VERSION ""

NS_ :

BS_:

BU_: XXX

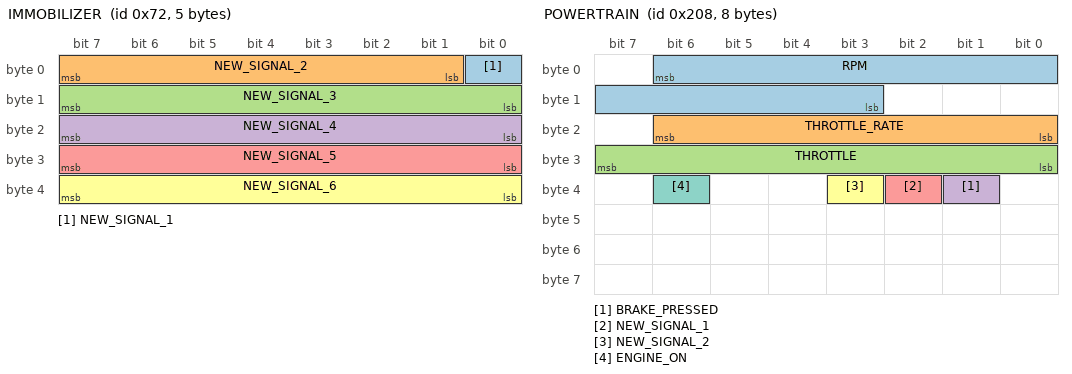
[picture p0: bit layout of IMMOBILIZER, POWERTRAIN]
BO_ 114 IMMOBILIZER: 5 XXX
 SG_ NEW_SIGNAL_1 : 0|1@0+ (1,0) [0|1] "" XXX
 SG_ NEW_SIGNAL_2 : 7|7@0+ (1,0) [0|127] "" XXX
 SG_ NEW_SIGNAL_3 : 15|8@0+ (1,0) [0|255] "" XXX
 SG_ NEW_SIGNAL_4 : 23|8@0+ (1,0) [0|255] "" XXX
 SG_ NEW_SIGNAL_5 : 31|8@0+ (1,0) [0|255] "" XXX
 SG_ NEW_SIGNAL_6 : 39|8@0+ (1,0) [0|255] "" XXX

BO_ 520 POWERTRAIN: 8 XXX
 SG_ RPM : 6|12@0+ (1,0) [0|8191] "" XXX
 SG_ THROTTLE_RATE : 22|7@0+ (1,0) [0|127] "" XXX
 SG_ THROTTLE : 31|8@0+ (0.5,0) [0|255] "" XXX
 SG_ BRAKE_PRESSED : 33|1@0+ (1,0) [0|1] "" XXX
 SG_ NEW_SIGNAL_1 : 34|1@0+ (1,0) [0|1] "" XXX
 SG_ NEW_SIGNAL_2 : 35|1@0+ (1,0) [0|1] "" XXX
 SG_ ENGINE_ON : 38|1@0+ (1,0) [0|1] "" XXX

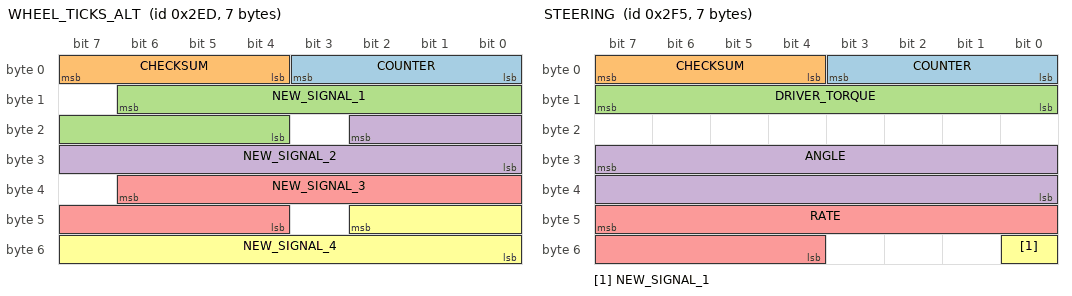
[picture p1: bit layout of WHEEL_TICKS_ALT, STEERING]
BO_ 749 WHEEL_TICKS_ALT: 7 XXX
 SG_ COUNTER : 3|4@0+ (1,0) [0|15] "" XXX
 SG_ CHECKSUM : 7|4@0+ (1,0) [0|15] "" XXX
 SG_ NEW_SIGNAL_1 : 14|11@0+ (1,0) [0|2047] "" XXX
 SG_ NEW_SIGNAL_2 : 18|11@0+ (1,0) [0|2047] "" XXX
 SG_ NEW_SIGNAL_3 : 38|11@0+ (1,0) [0|2047] "" XXX
 SG_ NEW_SIGNAL_4 : 42|11@0+ (1,0) [0|2047] "" XXX

BO_ 757 STEERING: 7 XXX
 SG_ COUNTER : 3|4@0+ (1,0) [0|255] "" XXX
 SG_ CHECKSUM : 7|4@0+ (1,0) [0|15] "" XXX
 SG_ DRIVER_TORQUE : 15|8@0- (1,0) [0|255] "" XXX
 SG_ ANGLE : 31|16@0- (0.1,0) [-3276.8|3276.7] "degrees" XXX
 SG_ RATE : 47|12@0- (1,0) [0|4095] "" XXX
 SG_ NEW_SIGNAL_1 : 48|1@0+ (1,0) [0|1] "" XXX

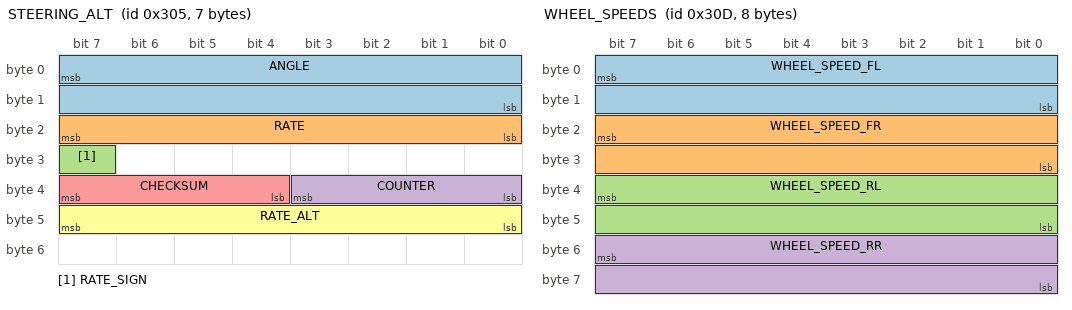
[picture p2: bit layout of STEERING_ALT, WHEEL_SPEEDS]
BO_ 773 STEERING_ALT: 7 XXX
 SG_ ANGLE : 7|16@0- (0.1,0) [-3276.8|3276.7] "degrees" XXX
 SG_ RATE : 23|8@0+ (1,0) [0|255] "" XXX
 SG_ RATE_SIGN : 31|1@0+ (1,0) [0|1] "" XXX
 SG_ COUNTER : 35|4@0+ (1,0) [0|255] "" XXX
 SG_ CHECKSUM : 39|4@0+ (1,0) [0|15] "" XXX
 SG_ RATE_ALT : 47|8@0+ (1,0) [0|255] "" XXX

BO_ 781 WHEEL_SPEEDS: 8 XXX
 SG_ WHEEL_SPEED_FL : 7|16@0+ (0.01,0) [0|65535] "kph" XXX
 SG_ WHEEL_SPEED_FR : 23|16@0+ (0.01,0) [0|65535] "kph" XXX
 SG_ WHEEL_SPEED_RL : 39|16@0+ (0.01,0) [0|65535] "kph" XXX
 SG_ WHEEL_SPEED_RR : 55|16@0+ (0.01,0) [0|65535] "kph" XXX

BO_ 840 BODY_2: 8 XXX
 SG_ GEAR : 7|4@0+ (1,0) [0|15] "" XXX
 SG_ NEW_SIGNAL_2 : 14|7@0+ (1,0) [0|127] "" XXX
 SG_ NEW_SIGNAL_1 : 22|7@0+ (1,0) [0|127] "" XXX
 SG_ NEW_SIGNAL_4 : 30|7@0+ (1,0) [0|127] "" XXX
 SG_ CLUTCH_PRESSED : 35|1@0+ (1,0) [0|1] "" XXX
 SG_ NEW_SIGNAL_9 : 37|1@0+ (1,0) [0|1] "" XXX
 SG_ NEW_SIGNAL_7 : 38|1@0+ (1,0) [0|1] "" XXX
 SG_ NEW_SIGNAL_6 : 39|1@0+ (1,0) [0|1] "" XXX
 SG_ NEW_SIGNAL_3 : 40|1@0+ (1,0) [0|1] "" XXX
 SG_ IGNITION : 41|1@0+ (1,0) [0|1] "" XXX
 SG_ NEW_SIGNAL_8 : 50|1@0+ (1,0) [0|1] "" XXX
 SG_ ENGINE_ON : 53|1@0+ (1,0) [0|1] "" XXX
 SG_ IGNITION_ACCESSORY : 54|1@0+ (1,0) [0|1] "" XXX
 SG_ NEW_SIGNAL_5 : 55|1@0+ (1,0) [0|1] "" XXX
 SG_ NEW_SIGNAL_13 : 56|1@0+ (1,0) [0|1] "" XXX
 SG_ NEW_SIGNAL_14 : 59|1@0+ (1,0) [0|1] "" XXX
 SG_ NEW_SIGNAL_15 : 60|1@0+ (1,0) [0|1] "" XXX

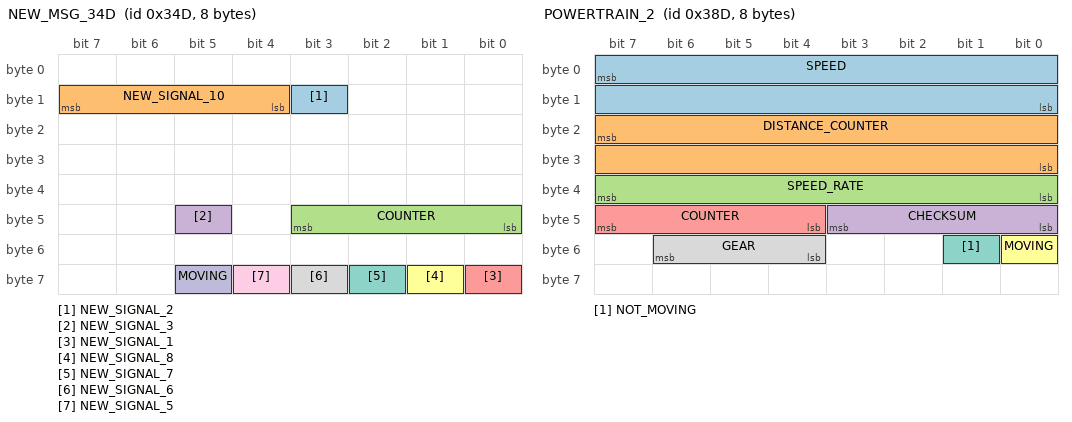
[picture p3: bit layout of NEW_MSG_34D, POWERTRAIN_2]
BO_ 845 NEW_MSG_34D: 8 XXX
 SG_ NEW_SIGNAL_2 : 11|1@0+ (1,0) [0|1] "" XXX
 SG_ NEW_SIGNAL_10 : 15|4@0+ (1,0) [0|15] "" XXX
 SG_ COUNTER : 43|4@0+ (1,0) [0|15] "" XXX
 SG_ NEW_SIGNAL_3 : 45|1@0+ (1,0) [0|1] "" XXX
 SG_ NEW_SIGNAL_1 : 56|1@0+ (1,0) [0|1] "" XXX
 SG_ NEW_SIGNAL_8 : 57|1@0+ (1,0) [0|1] "" XXX
 SG_ NEW_SIGNAL_7 : 58|1@0+ (1,0) [0|1] "" XXX
 SG_ NEW_SIGNAL_6 : 59|1@0+ (1,0) [0|1] "" XXX
 SG_ NEW_SIGNAL_5 : 60|1@0+ (1,0) [0|1] "" XXX
 SG_ MOVING : 61|1@0+ (1,0) [0|1] "" XXX

BO_ 909 POWERTRAIN_2: 8 XXX
 SG_ SPEED : 7|16@0+ (0.01,0) [0|655.35] "kph" XXX
 SG_ DISTANCE_COUNTER : 23|16@0+ (1,0) [0|65535] "" XXX
 SG_ SPEED_RATE : 39|8@0+ (1,-175) [0|255] "" XXX
 SG_ CHECKSUM : 43|4@0+ (1,0) [0|15] "" XXX
 SG_ COUNTER : 47|4@0+ (1,0) [0|15] "" XXX
 SG_ MOVING : 48|1@0+ (1,0) [0|1] "" XXX
 SG_ NOT_MOVING : 49|1@0+ (1,0) [0|1] "" XXX
 SG_ GEAR : 54|3@0+ (1,0) [0|7] "" XXX

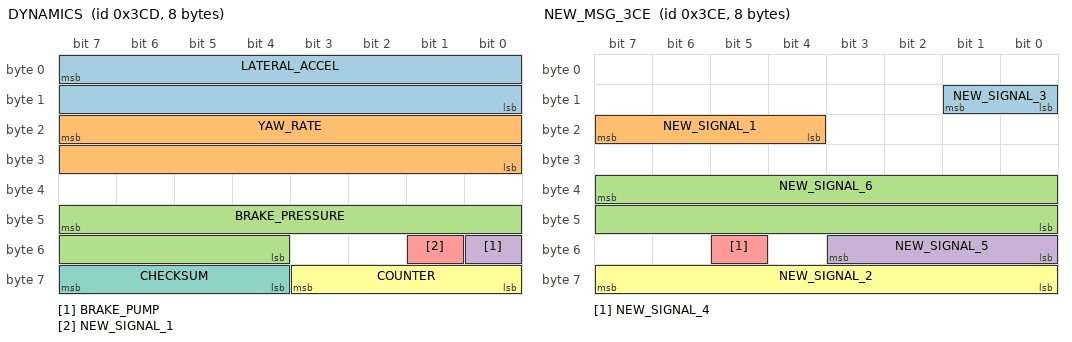
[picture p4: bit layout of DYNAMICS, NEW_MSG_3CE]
BO_ 973 DYNAMICS: 8 XXX
 SG_ LATERAL_ACCEL : 7|16@0- (0.05,0) [-1638.4|1638.35] "m/s^2" XXX
 SG_ YAW_RATE : 23|16@0- (0.1,0) [-3276.8|3276.7] "degrees/s" XXX
 SG_ BRAKE_PRESSURE : 47|12@0+ (1,-550) [0|1500] "" XXX
 SG_ BRAKE_PUMP : 48|1@0+ (1,0) [0|1] "" XXX
 SG_ NEW_SIGNAL_1 : 49|1@0+ (1,0) [0|1] "" XXX
 SG_ COUNTER : 59|4@0+ (1,0) [0|15] "" XXX
 SG_ CHECKSUM : 63|4@0+ (1,0) [0|15] "" XXX

BO_ 974 NEW_MSG_3CE: 8 XXX
 SG_ NEW_SIGNAL_3 : 9|2@0+ (1,0) [0|3] "" XXX
 SG_ NEW_SIGNAL_1 : 23|4@0+ (1,0) [0|15] "" XXX
 SG_ NEW_SIGNAL_6 : 39|16@0+ (1,0) [0|65535] "" XXX
 SG_ NEW_SIGNAL_5 : 51|4@0+ (1,0) [0|15] "" XXX
 SG_ NEW_SIGNAL_4 : 53|1@0+ (1,0) [0|1] "" XXX
 SG_ NEW_SIGNAL_2 : 63|8@0+ (1,0) [0|255] "" XXX

BO_ 1010 LANE_KEEP_ASSIST: 8 XXX
 SG_ NEW_SIGNAL_8 : 0|1@0+ (1,0) [0|1] "" XXX
 SG_ NEW_SIGNAL_1 : 3|3@0+ (1,0) [0|7] "" XXX
 SG_ NEW_SIGNAL_7 : 4|1@0+ (1,0) [0|1] "" XXX
 SG_ NEW_SIGNAL_12 : 5|1@0+ (1,0) [0|1] "" XXX
 SG_ COUNTER : 11|4@0+ (1,0) [0|15] "" XXX
 SG_ CHECKSUM : 15|4@0+ (1,0) [0|15] "" XXX
 SG_ NEW_SIGNAL_6 : 17|2@0+ (1,0) [0|3] "" XXX
 SG_ NEW_SIGNAL_5 : 19|2@0+ (1,0) [0|3] "" XXX
 SG_ LOW_SPEED : 21|2@0+ (1,0) [0|3] "" XXX
 SG_ TORQUE : 31|11@0- (1,0) [0|2047] "" XXX
 SG_ RIGHT_DEPART : 32|1@0+ (1,0) [0|1] "" XXX
 SG_ LEFT_DEPART : 33|1@0+ (1,0) [0|1] "" XXX
 SG_ LKA_DENY : 34|1@0+ (1,0) [0|1] "" XXX
 SG_ STATUS : 35|1@0+ (1,0) [0|1] "" XXX
 SG_ ACTIVE : 36|1@0+ (1,0) [0|1] "" XXX
 SG_ RAMP : 47|7@0+ (1,0) [0|127] "" XXX
 SG_ ANGLE : 55|14@0- (0.1,0) [-90|90] "" XXX
 SG_ NEW_SIGNAL_10 : 57|1@0+ (1,0) [0|1] "" XXX

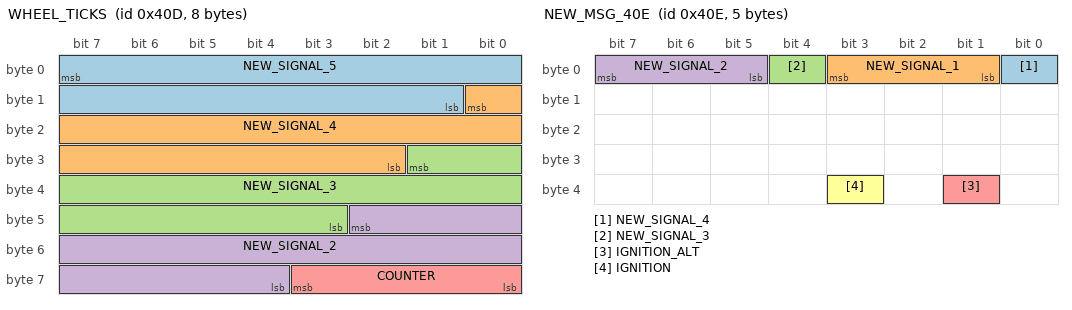
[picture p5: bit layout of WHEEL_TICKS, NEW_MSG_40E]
BO_ 1037 WHEEL_TICKS: 8 XXX
 SG_ NEW_SIGNAL_5 : 7|15@0+ (1,0) [0|32767] "" XXX
 SG_ NEW_SIGNAL_4 : 8|15@0+ (1,0) [0|32767] "" XXX
 SG_ NEW_SIGNAL_3 : 25|15@0+ (1,0) [0|32767] "" XXX
 SG_ NEW_SIGNAL_2 : 42|15@0+ (1,0) [0|32767] "" XXX
 SG_ COUNTER : 59|4@0+ (1,0) [0|15] "" XXX

BO_ 1038 NEW_MSG_40E: 5 XXX
 SG_ NEW_SIGNAL_4 : 0|1@0+ (1,0) [0|1] "" XXX
 SG_ NEW_SIGNAL_1 : 1|3@1+ (1,0) [0|7] "" XXX
 SG_ NEW_SIGNAL_3 : 4|1@0+ (1,0) [0|1] "" XXX
 SG_ NEW_SIGNAL_2 : 5|3@1+ (1,0) [0|7] "" XXX
 SG_ IGNITION_ALT : 33|1@0+ (1,0) [0|1] "" XXX
 SG_ IGNITION : 35|1@0+ (1,0) [0|1] "" XXX

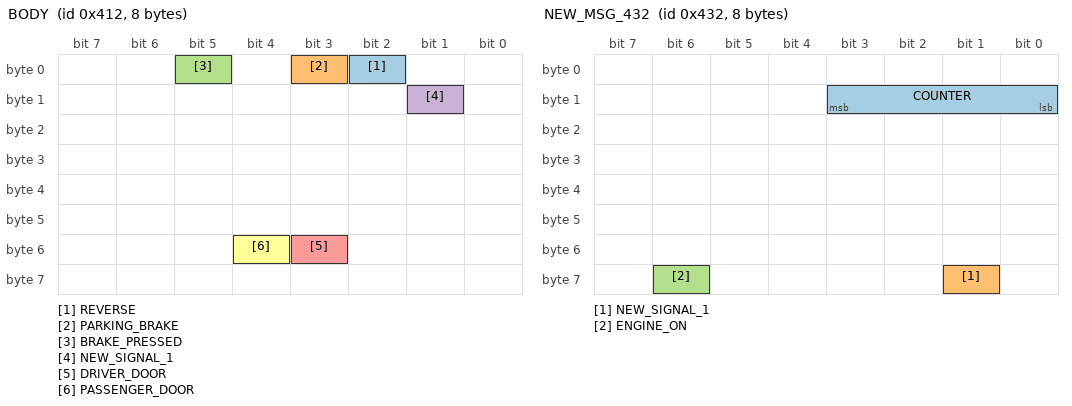
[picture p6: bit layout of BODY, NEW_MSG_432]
BO_ 1042 BODY: 8 XXX
 SG_ REVERSE : 2|1@0+ (1,0) [0|1] "" XXX
 SG_ PARKING_BRAKE : 3|1@0+ (1,0) [0|1] "" XXX
 SG_ BRAKE_PRESSED : 5|1@0+ (1,0) [0|1] "" XXX
 SG_ NEW_SIGNAL_1 : 9|1@0+ (1,0) [0|1] "" XXX
 SG_ DRIVER_DOOR : 51|1@0+ (1,0) [0|1] "" XXX
 SG_ PASSENGER_DOOR : 52|1@0+ (1,0) [0|1] "" XXX

BO_ 1074 NEW_MSG_432: 8 XXX
 SG_ COUNTER : 8|4@1+ (1,0) [0|15] "" XXX
 SG_ NEW_SIGNAL_1 : 57|1@0+ (1,0) [0|1] "" XXX
 SG_ ENGINE_ON : 62|1@0+ (1,0) [0|1] "" XXX

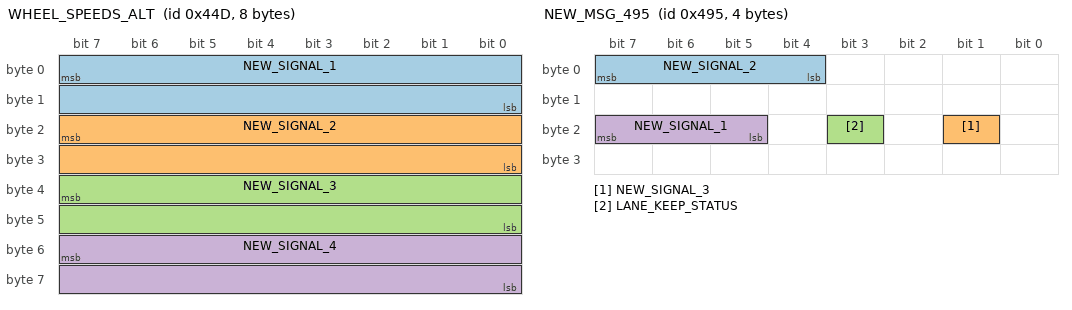
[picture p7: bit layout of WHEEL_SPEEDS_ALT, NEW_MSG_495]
BO_ 1101 WHEEL_SPEEDS_ALT: 8 XXX
 SG_ NEW_SIGNAL_1 : 7|16@0+ (0.01,0) [0|655.35] "kph" XXX
 SG_ NEW_SIGNAL_2 : 23|16@0+ (0.01,0) [0|655.35] "kph" XXX
 SG_ NEW_SIGNAL_3 : 39|16@0+ (0.01,0) [0|655.35] "kph" XXX
 SG_ NEW_SIGNAL_4 : 55|16@0+ (0.005,0) [0|327.675] "kph" XXX

BO_ 1128 NEW_MSG_468: 8 XXX
 SG_ ENGINE_ON2 : 5|1@0+ (1,0) [0|1] "" XXX
 SG_ NEW_SIGNAL_6 : 8|1@0+ (1,0) [0|1] "" XXX
 SG_ NEW_SIGNAL_7 : 10|1@0+ (1,0) [0|1] "" XXX
 SG_ ENGINE_ON : 11|1@0+ (1,0) [0|1] "" XXX
 SG_ NEW_SIGNAL_2 : 13|2@0+ (1,0) [0|3] "" XXX
 SG_ NEW_SIGNAL_9 : 16|1@0+ (1,0) [0|1] "" XXX
 SG_ NEW_SIGNAL_8 : 22|1@0+ (1,0) [0|1] "" XXX
 SG_ NEW_SIGNAL_3 : 25|6@0+ (1,0) [0|63] "" XXX
 SG_ NEW_SIGNAL_14 : 27|1@0+ (1,0) [0|1] "" XXX
 SG_ NEW_SIGNAL_12 : 28|1@0+ (1,0) [0|1] "" XXX
 SG_ NEW_SIGNAL_10 : 31|2@0+ (1,0) [0|3] "" XXX
 SG_ NEW_SIGNAL_17 : 40|1@0+ (1,0) [0|1] "" XXX
 SG_ IGNITION_ALT2 : 41|1@0+ (1,0) [0|1] "" XXX
 SG_ IGNITION_ALT : 42|1@0+ (1,0) [0|1] "" XXX
 SG_ NEW_SIGNAL_18 : 47|1@0+ (1,0) [0|1] "" XXX
 SG_ NEW_SIGNAL_1 : 52|1@0+ (1,0) [0|1] "" XXX
 SG_ NEW_SIGNAL_19 : 61|1@0+ (1,0) [0|1] "" XXX
 SG_ NEW_SIGNAL_13 : 62|1@0+ (1,0) [0|1] "" XXX
 SG_ NEW_SIGNAL_11 : 63|1@0+ (1,0) [0|1] "" XXX

BO_ 1173 NEW_MSG_495: 4 XXX
 SG_ NEW_SIGNAL_2 : 7|4@0+ (1,0) [0|15] "" XXX
 SG_ NEW_SIGNAL_3 : 17|1@0+ (1,0) [0|1] "" XXX
 SG_ LANE_KEEP_STATUS : 19|1@0+ (1,0) [0|1] "" XXX
 SG_ NEW_SIGNAL_1 : 23|3@0+ (1,0) [0|7] "" XXX

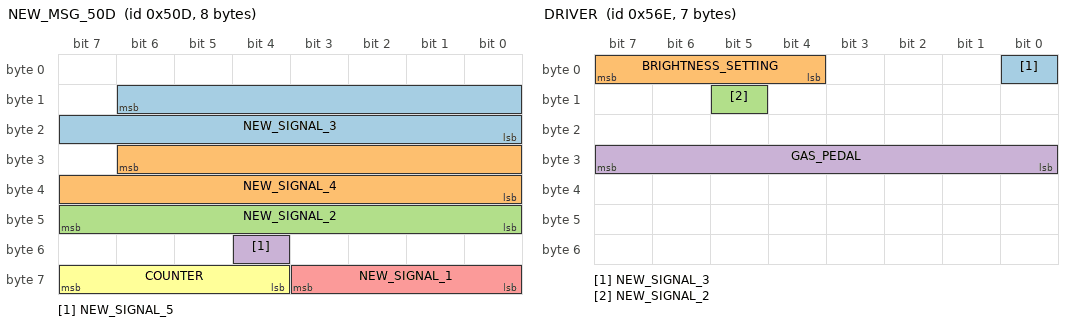
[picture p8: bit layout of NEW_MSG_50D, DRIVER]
BO_ 1293 NEW_MSG_50D: 8 XXX
 SG_ NEW_SIGNAL_3 : 14|15@0+ (1,0) [0|32767] "" XXX
 SG_ NEW_SIGNAL_4 : 30|15@0+ (1,0) [0|32767] "" XXX
 SG_ NEW_SIGNAL_2 : 47|8@0+ (1,0) [0|255] "" XXX
 SG_ NEW_SIGNAL_5 : 52|1@0+ (1,0) [0|1] "" XXX
 SG_ NEW_SIGNAL_1 : 59|4@0+ (1,0) [0|15] "" XXX
 SG_ COUNTER : 63|4@0+ (1,0) [0|15] "" XXX

BO_ 1358 NEW_MSG_54E: 8 XXX
 SG_ NEW_SIGNAL_2 : 48|1@0+ (1,0) [0|1] "" XXX

BO_ 1362 CLOCKS: 8 XXX

BO_ 1390 DRIVER: 7 XXX
 SG_ NEW_SIGNAL_3 : 0|1@0+ (1,0) [0|1] "" XXX
 SG_ BRIGHTNESS_SETTING : 7|4@0+ (1,0) [0|15] "" XXX
 SG_ NEW_SIGNAL_2 : 13|1@0+ (1,0) [0|1] "" XXX
 SG_ GAS_PEDAL : 31|8@0+ (0.5,0) [0|99.5] "%" XXX

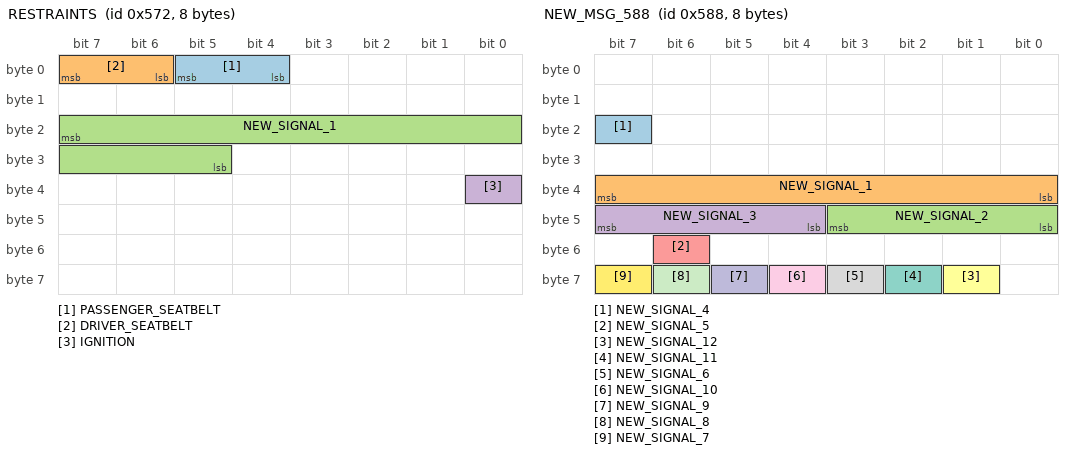
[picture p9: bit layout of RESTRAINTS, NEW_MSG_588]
BO_ 1394 RESTRAINTS: 8 XXX
 SG_ PASSENGER_SEATBELT : 5|2@0+ (1,0) [0|3] "" XXX
 SG_ DRIVER_SEATBELT : 7|2@0+ (1,0) [0|3] "" XXX
 SG_ NEW_SIGNAL_1 : 23|11@0+ (1,0) [0|1] "" XXX
 SG_ IGNITION : 32|1@0+ (1,0) [0|1] "" XXX

BO_ 1416 NEW_MSG_588: 8 XXX
 SG_ NEW_SIGNAL_4 : 23|1@0+ (1,0) [0|1] "" XXX
 SG_ NEW_SIGNAL_1 : 39|8@0+ (1,0) [0|255] "" XXX
 SG_ NEW_SIGNAL_2 : 43|4@0+ (1,0) [0|15] "" XXX
 SG_ NEW_SIGNAL_3 : 47|4@0+ (1,0) [0|15] "" XXX
 SG_ NEW_SIGNAL_5 : 54|1@0+ (1,0) [0|1] "" XXX
 SG_ NEW_SIGNAL_12 : 57|1@0+ (1,0) [0|1] "" XXX
 SG_ NEW_SIGNAL_11 : 58|1@0+ (1,0) [0|1] "" XXX
 SG_ NEW_SIGNAL_6 : 59|1@0+ (1,0) [0|1] "" XXX
 SG_ NEW_SIGNAL_10 : 60|1@0+ (1,0) [0|1] "" XXX
 SG_ NEW_SIGNAL_9 : 61|1@0+ (1,0) [0|1] "" XXX
 SG_ NEW_SIGNAL_8 : 62|1@0+ (1,0) [0|1] "" XXX
 SG_ NEW_SIGNAL_7 : 63|1@0+ (1,0) [0|1] "" XXX

BO_ 1485 NEW_MSG_5CD: 4 XXX
 SG_ COUNTER : 3|4@0+ (1,0) [0|15] "" XXX
 SG_ CHECKSUM : 7|4@0+ (1,0) [0|15] "" XXX

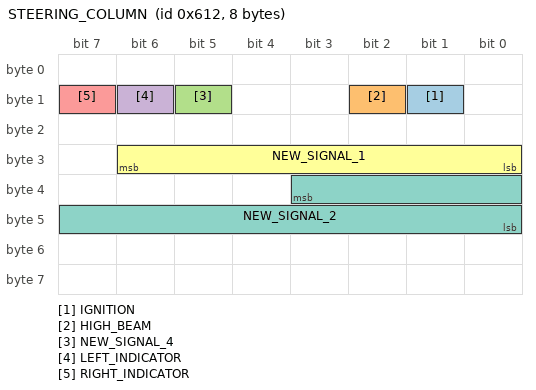
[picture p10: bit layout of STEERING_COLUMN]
BO_ 1554 STEERING_COLUMN: 8 XXX
 SG_ IGNITION : 9|1@0+ (1,0) [0|1] "" XXX
 SG_ HIGH_BEAM : 10|1@0+ (1,0) [0|1] "" XXX
 SG_ NEW_SIGNAL_4 : 13|1@0+ (1,0) [0|1] "" XXX
 SG_ LEFT_INDICATOR : 14|1@0+ (1,0) [0|1] "" XXX
 SG_ RIGHT_INDICATOR : 15|1@0+ (1,0) [0|1] "" XXX
 SG_ NEW_SIGNAL_1 : 30|7@0+ (1,0) [0|127] "" XXX
 SG_ NEW_SIGNAL_2 : 35|12@0+ (1,0) [0|31] "" XXX

CM_ SG_ 520 NEW_SIGNAL_1 "high when limiter NOT set/ready";
CM_ SG_ 520 NEW_SIGNAL_2 "high when limiter NOT set/ready";
CM_ SG_ 520 ENGINE_ON "after ignition, rpm stable? (slow)";
CM_ SG_ 757 ANGLE "asymmetric, could be init";
CM_ SG_ 773 ANGLE "-565 to 560, seems like estimate and not init";
CM_ SG_ 773 RATE_SIGN "1=moving clockwise, 0=moving anticlockwise";
CM_ SG_ 781 WHEEL_SPEED_FL "left?";
CM_ SG_ 781 WHEEL_SPEED_FR "right";
CM_ SG_ 781 WHEEL_SPEED_RL "front? left?";
CM_ SG_ 781 WHEEL_SPEED_RR "front right?";
CM_ SG_ 840 NEW_SIGNAL_9 "related to clutch?";
CM_ SG_ 840 NEW_SIGNAL_7 "high on accessory mode, low on engine";
CM_ SG_ 840 NEW_SIGNAL_6 "high on accessory mode, low on engine";
CM_ SG_ 840 NEW_SIGNAL_3 "low while ignition cranking";
CM_ SG_ 840 IGNITION "when key turned to ignition";
CM_ SG_ 840 NEW_SIGNAL_8 "high when clutched pressed/until engine ready. could be wake signal?";
CM_ SG_ 840 ENGINE_ON "slightly later?";
CM_ SG_ 840 IGNITION_ACCESSORY "high on accessory, high on engine";
CM_ SG_ 840 NEW_SIGNAL_5 "low on accessory";
CM_ SG_ 840 NEW_SIGNAL_13 "not ignition";
CM_ SG_ 840 NEW_SIGNAL_14 "not ignition";
CM_ SG_ 840 NEW_SIGNAL_15 "not ignition";
CM_ SG_ 909 MOVING ">5kph approx";
CM_ SG_ 909 NOT_MOVING "<5kph approx";
CM_ SG_ 973 LATERAL_ACCEL "positive is left";
CM_ SG_ 973 YAW_RATE "positive is left";
CM_ SG_ 973 BRAKE_PUMP "seems related to brake pressure. can sometimes be HIGH even after brake not pressed.";
CM_ SG_ 1010 LKA_DENY "1=LKA OFF (button in console)";
CM_ SG_ 1010 STATUS "0=LKA OFF (button in console), 1=LKA AVAILABLE";
CM_ SG_ 1038 IGNITION_ALT "one frame behind IGNITION";
CM_ SG_ 1038 IGNITION "doesn't turn off straight away";
CM_ SG_ 1074 ENGINE_ON "slow";
CM_ SG_ 1101 NEW_SIGNAL_1 "FR + FL?";
CM_ SG_ 1101 NEW_SIGNAL_2 "RL?";
CM_ SG_ 1101 NEW_SIGNAL_3 "RR?";
CM_ SG_ 1128 ENGINE_ON2 "slightly slower";
CM_ SG_ 1128 IGNITION_ALT2 "doesn't turn off straight away. low while cranking";
CM_ SG_ 1128 IGNITION_ALT "doesn't turn off straight away, odd behaviour around cranking";
CM_ SG_ 1390 GAS_PEDAL "Max 99.5%";
CM_ SG_ 1394 IGNITION "doesn't turn off straight away";
CM_ SG_ 1416 NEW_SIGNAL_1 "rpm related?";
CM_ SG_ 1554 IGNITION "doesn't turn off straight away";
CM_ SG_ 1554 NEW_SIGNAL_4 "high on accessory";
VAL_ 909 GEAR 2 "REVERSE";
VAL_ 1042 DRIVER_DOOR 0 "CLOSED" 1 "OPEN";
